# HDSC_HC32F160 register map
Vendor: HDSC Co.,Ltd.; Series: ARMCM0P; File version: 1.0
CPU: CM0P r0p1, little endian, MPU, FPU, 4 interrupt priority bits
Registers are 32-bit, read-write, reset 0x0 unless marked. A register's access mark holds for its fields unless they carry their own. Offsets are from the block's base; [hi:lo] are bit positions; {n}, {i} and the like mark numbered series; 'fields as' and 'values as' point back to an identical list.

## DBGC_T
Base 0xE0042000
{0x0+4i} AUTHID{i} (i=0..2)
0x0C RESV0
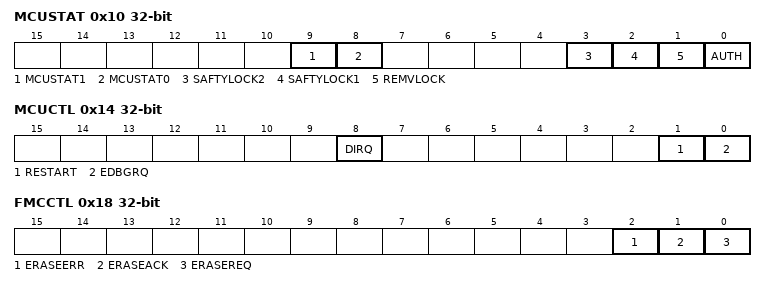
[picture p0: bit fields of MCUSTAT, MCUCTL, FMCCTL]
0x10 MCUSTAT
  [9] MCUSTAT1, [8] MCUSTAT0, [3] SAFTYLOCK2, [2] SAFTYLOCK1, [1] REMVLOCK, [0] AUTH
0x14 MCUCTL
  [8] DIRQ, [1] RESTART, [0] EDBGRQ
0x18 FMCCTL
  [2] ERASEERR, [1] ERASEACK, [0] ERASEREQ

## DMA
Base 0x40013000
0x00 EN
  [0] EN
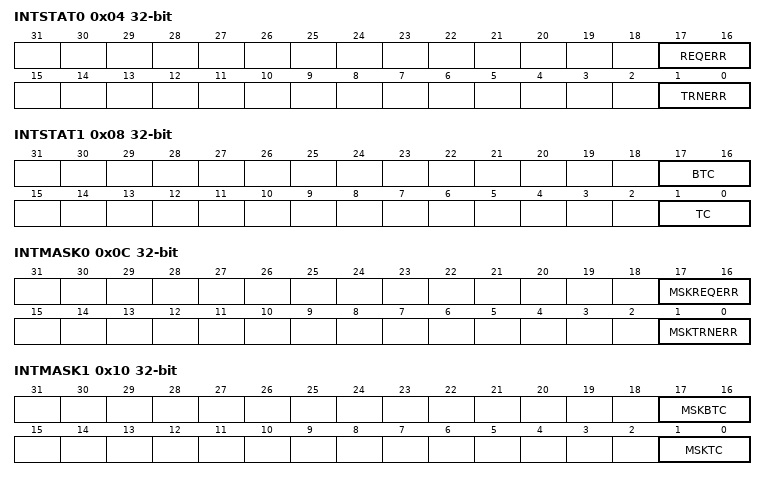
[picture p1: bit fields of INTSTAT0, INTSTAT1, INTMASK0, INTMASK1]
0x04 INTSTAT0 ro
  [17:16] REQERR, [1:0] TRNERR
0x08 INTSTAT1 ro
  [17:16] BTC, [1:0] TC
0x0C INTMASK0
  [17:16] MSKREQERR, [1:0] MSKTRNERR
0x10 INTMASK1
  [17:16] MSKBTC, [1:0] MSKTC
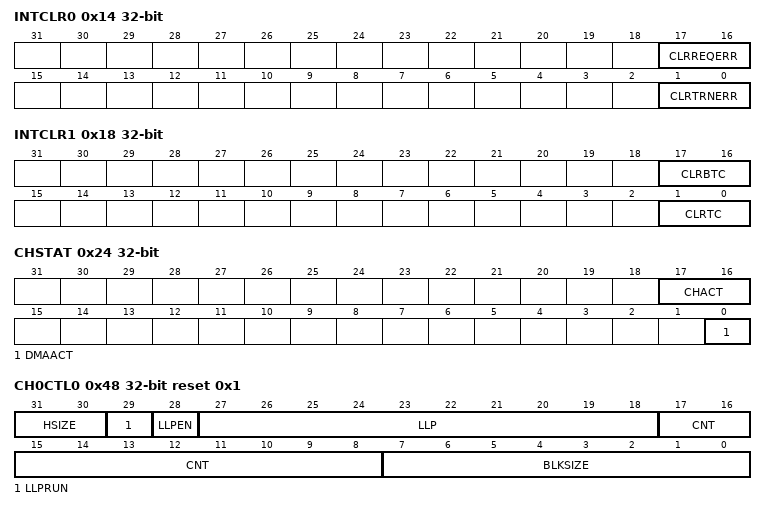
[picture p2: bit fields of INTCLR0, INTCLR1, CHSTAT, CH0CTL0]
0x14 INTCLR0 wo
  [17:16] CLRREQERR, [1:0] CLRTRNERR
0x18 INTCLR1 wo
  [17:16] CLRBTC, [1:0] CLRTC
0x1C CHEN
  [1:0] CHEN
0x24 CHSTAT ro
  [17:16] CHACT, [0] DMAACT
0x30 BASE1_LLP reset 0x20000000
  [31:14] LLP
0x34 BASE2_LLP
  [31:14] LLP
0x38 CHENCLR
  [1:0] CHENCLR
0x40 SAR0
0x44 DAR0
0x48 CH0CTL0 reset 0x1
  [31:30] HSIZE, [29] LLPRUN, [28] LLPEN, [27:18] LLP, [17:8] CNT, [7:0] BLKSIZE
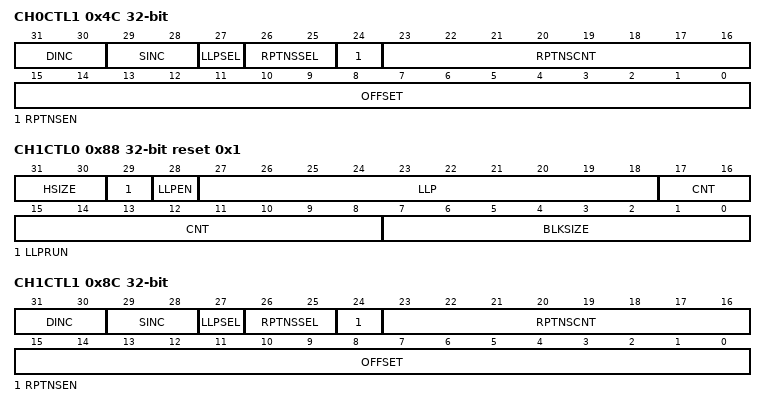
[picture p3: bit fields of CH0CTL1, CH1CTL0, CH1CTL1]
0x4C CH0CTL1
  [31:30] DINC, [29:28] SINC, [27] LLPSEL, [26:25] RPTNSSEL, [24] RPTNSEN, [23:16] RPTNSCNT, [15:0] OFFSET
0x80 SAR1
0x84 DAR1
0x88 CH1CTL0 reset 0x1
  fields as CH0CTL0
0x8C CH1CTL1
  fields as CH0CTL1

## EFM
Base 0x40000800
0x00 FAPRT
  [15:0] FAPRT
0x04 FSTP
  [0] FSTP
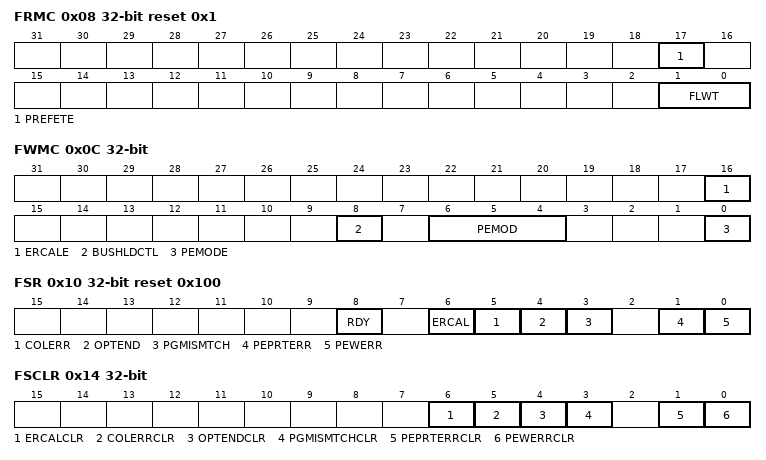
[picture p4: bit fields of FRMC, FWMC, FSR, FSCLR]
0x08 FRMC reset 0x1
  [17] PREFETE, [1:0] FLWT
0x0C FWMC
  [16] ERCALE, [8] BUSHLDCTL, [6:4] PEMOD, [0] PEMODE
0x10 FSR ro reset 0x100
  [8] RDY, [6] ERCAL rw, [5] COLERR, [4] OPTEND, [3] PGMISMTCH, [1] PEPRTERR, [0] PEWERR
0x14 FSCLR
  [6] ERCALCLR, [5] COLERRCLR, [4] OPTENDCLR, [3] PGMISMTCHCLR, [1] PEPRTERRCLR, [0] PEWERRCLR
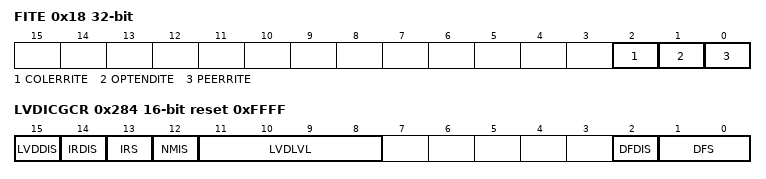
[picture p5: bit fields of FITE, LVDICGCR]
0x18 FITE
  [2] COLERRITE, [1] OPTENDITE, [0] PEERRITE
0x20 FPMTSW
  [17:0] FPMTSW
0x24 FPMTEW
  [17:0] FPMTEW
{0x50+4i} UQID{i} ro (i=0..2)
0x282 HRCCFGR 8-bit
  [3:0] HRCFREQS
0x284 LVDICGCR 16-bit reset 0xFFFF
  [15] LVDDIS, [14] IRDIS, [13] IRS, [12] NMIS, [11:8] LVDLVL, [2] DFDIS, [1:0] DFS

## I2C
Base 0x40004800
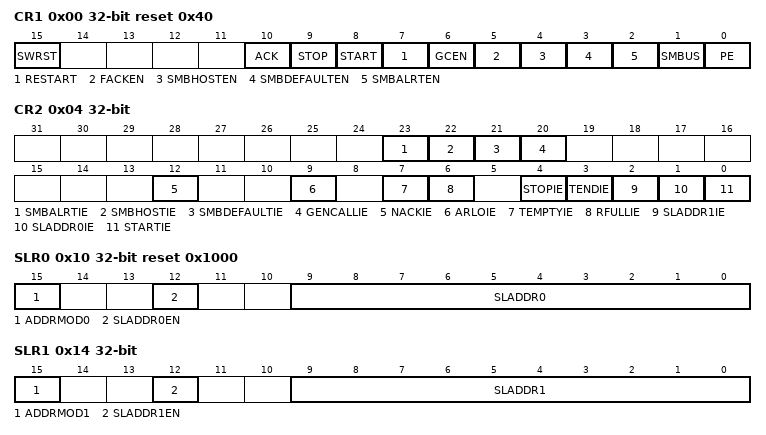
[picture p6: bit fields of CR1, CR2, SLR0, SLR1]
0x00 CR1 reset 0x40
  [15] SWRST, [10] ACK, [9] STOP, [8] START, [7] RESTART, [6] GCEN, [5] FACKEN, [4] SMBHOSTEN, [3] SMBDEFAULTEN, [2] SMBALRTEN, [1] SMBUS, [0] PE
0x04 CR2
  [23] SMBALRTIE, [22] SMBHOSTIE, [21] SMBDEFAULTIE, [20] GENCALLIE, [12] NACKIE, [9] ARLOIE, [7] TEMPTYIE, [6] RFULLIE, [4] STOPIE, [3] TENDIE, [2] SLADDR1IE, [1] SLADDR0IE, [0] STARTIE
0x10 SLR0 reset 0x1000
  [15] ADDRMOD0, [12] SLADDR0EN, [9:0] SLADDR0
0x14 SLR1
  [15] ADDRMOD1, [12] SLADDR1EN, [9:0] SLADDR1
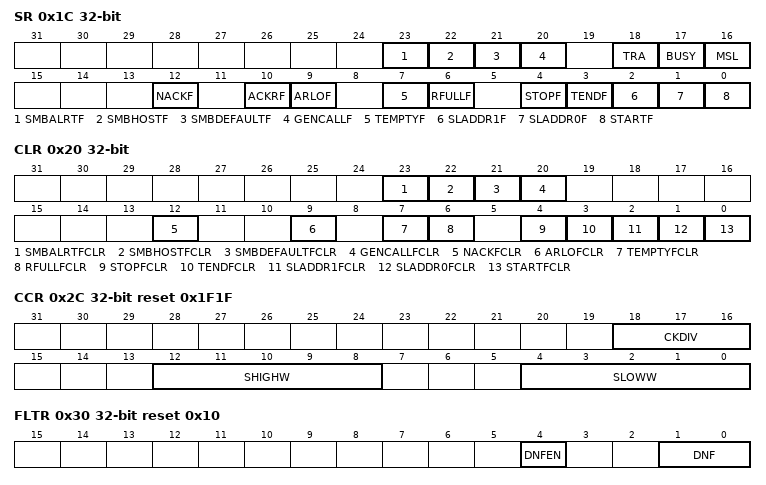
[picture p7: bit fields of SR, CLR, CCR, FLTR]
0x1C SR ro
  [23] SMBALRTF, [22] SMBHOSTF, [21] SMBDEFAULTF, [20] GENCALLF, [18] TRA rw, [17] BUSY, [16] MSL rw, [12] NACKF, [10] ACKRF, [9] ARLOF, [7] TEMPTYF, [6] RFULLF, [4] STOPF, [3] TENDF, [2] SLADDR1F, [1] SLADDR0F, [0] STARTF
0x20 CLR wo
  [23] SMBALRTFCLR, [22] SMBHOSTFCLR, [21] SMBDEFAULTFCLR, [20] GENCALLFCLR, [12] NACKFCLR, [9] ARLOFCLR, [7] TEMPTYFCLR, [6] RFULLFCLR, [4] STOPFCLR, [3] TENDFCLR, [2] SLADDR1FCLR, [1] SLADDR0FCLR, [0] STARTFCLR
0x24 DTR 8-bit reset 0xFF
  [7:0] DT
0x28 DRR 8-bit
  [7:0] DR
0x2C CCR reset 0x1F1F
  [18:16] CKDIV, [12:8] SHIGHW, [4:0] SLOWW
0x30 FLTR reset 0x10
  [4] DNFEN, [1:0] DNF

## ICG
Base 0x000000C0
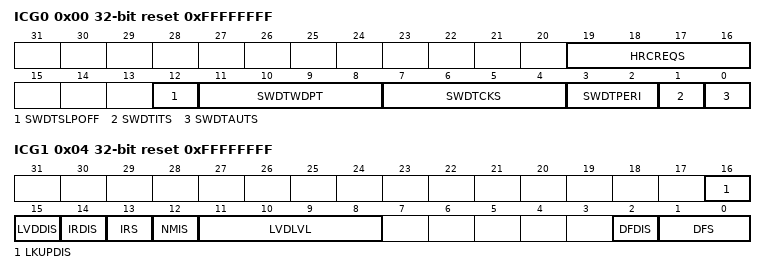
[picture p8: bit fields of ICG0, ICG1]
0x00 ICG0 ro reset 0xFFFFFFFF
  [19:16] HRCREQS, [12] SWDTSLPOFF, [11:8] SWDTWDPT, [7:4] SWDTCKS, [3:2] SWDTPERI, [1] SWDTITS, [0] SWDTAUTS
0x04 ICG1 ro reset 0xFFFFFFFF
  [16] LKUPDIS, [15] LVDDIS, [14] IRDIS, [13] IRS, [12] NMIS, [11:8] LVDLVL, [2] DFDIS, [1:0] DFS
{0x0+4i} ICG{i} ro reset 0xFFFFFFFF (reset mask 0x0) (i=2..6)

## INTC
Base 0x40011000
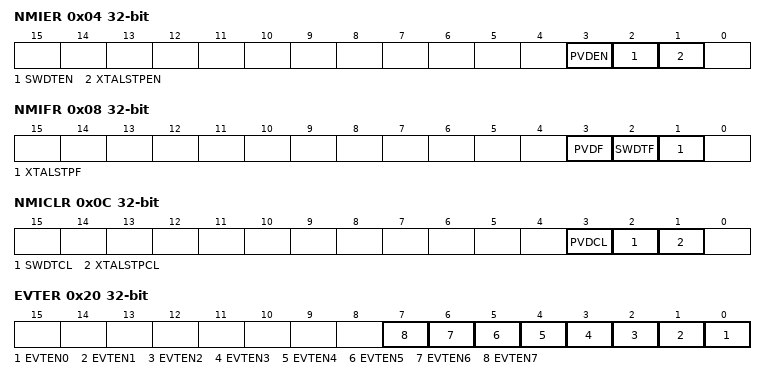
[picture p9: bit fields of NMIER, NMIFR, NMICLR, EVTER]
0x04 NMIER
  [3] PVDEN, [2] SWDTEN, [1] XTALSTPEN
0x08 NMIFR ro
  [3] PVDF, [2] SWDTF, [1] XTALSTPF
0x0C NMICLR
  [3] PVDCL, [2] SWDTCL, [1] XTALSTPCL
0x20 EVTER
  [n] EVTEN{n} (n=0..7)
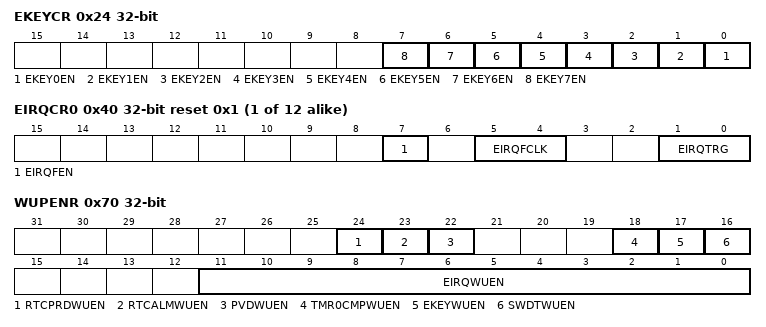
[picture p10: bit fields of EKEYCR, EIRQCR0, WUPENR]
0x24 EKEYCR
  [n] EKEY{n}EN (n=0..7)
0x3C FPRCR
  [7:0] FPRC
{0x40+4i} EIRQCR{i} reset 0x1 (i=0..11)
  [7] EIRQFEN, [5:4] EIRQFCLK, [1:0] EIRQTRG
0x70 WUPENR
  [24] RTCPRDWUEN, [23] RTCALMWUEN, [22] PVDWUEN, [18] TMR0CMPWUEN, [17] EKEYWUEN, [16] SWDTWUEN, [11:0] EIRQWUEN
0x74 EIRQFR
  [11:0] EIRQF
0x78 EIRQCLR
  [11:0] EIRQCL
{0x80+4i} ISELR{i} (i=8..23)
  [3:0] ISEL
{0x80+4i} ISELR{i} (i=24..31)
  [15:1] ISEL
